# MAIN_SEC_MMR0_CFG0 register map
Vendor: Texas Instruments
Peripheral module from a debugger description file (folder J722S).
Registers are 32-bit, read-write, reset 0x0 unless marked. A register's access mark holds for its fields unless they carry their own. Offsets are as the file gives them; lines under a group give offsets from that group; [hi:lo] are bit positions; {n}, {i} and the like mark numbered series; 'fields as' and 'values as' point back to an identical list; <NAME> marks a mode.

## MAIN_SEC_MMR0_CFG0
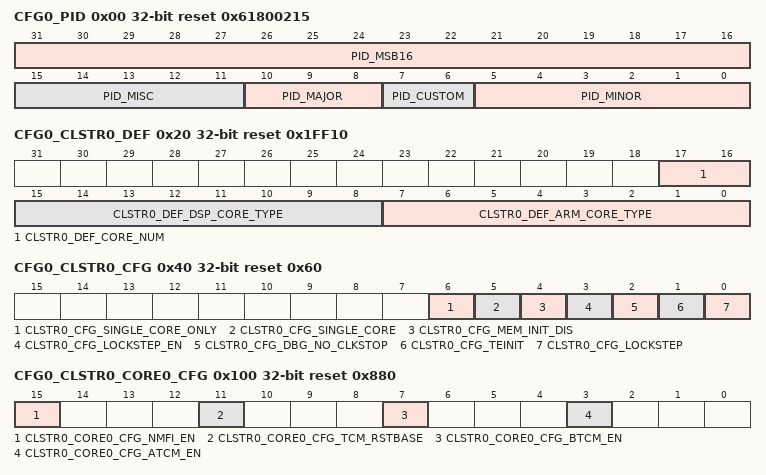
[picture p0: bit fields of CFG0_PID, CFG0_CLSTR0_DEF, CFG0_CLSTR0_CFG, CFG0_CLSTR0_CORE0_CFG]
0x00 CFG0_PID ro reset 0x61800215
  [31:16] PID_MSB16, [15:11] PID_MISC, [10:8] PID_MAJOR, [7:6] PID_CUSTOM, [5:0] PID_MINOR
0x20 CFG0_CLSTR0_DEF ro reset 0x1FF10
  [17:16] CLSTR0_DEF_CORE_NUM — Number of cores in cluster 001 - Single Core 010 - Dual Core
  [15:8] CLSTR0_DEF_DSP_CORE_TYPE — DSP core type configuration Field values (others are reserved): 8'h00 - C7x 8'h01 - C6x 8'h10 - AC7x 8'hFF - Not DSP
  [7:0] CLSTR0_DEF_ARM_CORE_TYPE — ARM core type configuration Field values (others are reserved): 8'h01 - A57 8'h10 - R5 8'h11 - M4F 8'hFF - Not ARM 8'h00 - A53 8'h01 - A57 8'h10 - R5 8'h11 - M4F 8'hFF - Not ARM
0x40 CFG0_CLSTR0_CFG access per field reset 0x60
  [6] CLSTR0_CFG_SINGLE_CORE_ONLY ro — Single / Dual CPU Mode Supported: 0 = Both Dual and Single Core are supported 1 = Only Single Core Mode is Supported
  [5] CLSTR0_CFG_SINGLE_CORE ro — Single / Dual CPU Mode: 0 = Unsupported on this device 1 = Only CPU0 is active.
  [4] CLSTR0_CFG_MEM_INIT_DIS rw — Deactivates SRAM initialization (TCM, Cache Tags, etc) at reset Initialization must be performed for proper initial ECC initialization. The mem_init_dis value must be selected prior to R5 reset assertion. 1'b0 - Perform memory initialization 1'b1 - Deactivate memory initialization
  [3] CLSTR0_CFG_LOCKSTEP_EN ro — Lockstep Not Supported
  [2] CLSTR0_CFG_DBG_NO_CLKSTOP rw — CPU clockstop behavior 0 - CPU clocks stopped and nCLOCKSTOPPED asserted in standby mode 1 - CPU clocks not stopped in standby mode
  [1] CLSTR0_CFG_TEINIT rw — Exception handling state at reset: 0 - ARM mode 1 - Thumb mode CAUTION: This bit must not be modified while R5F CPU is released from reset.
  [0] CLSTR0_CFG_LOCKSTEP ro — Lockstep Not Supported
0x80 CFG0_CLSTR0_PMCTRL access not given reset not defined
0x90 CFG0_CLSTR0_PMSTAT access not given reset not defined
0x100 CFG0_CLSTR0_CORE0_CFG reset 0x880
  [15] CLSTR0_CORE0_CFG_NMFI_EN — Activate Core0 Non-Maskable Fast Interrupts CAUTION: This bit must not be modified while R5F CPU is released from reset.
  [11] CLSTR0_CORE0_CFG_TCM_RSTBASE — Core0 A/BTCM Reset Base Address Indicator 0 - BTCM located at address 0x0 1 - ATCM located at address 0x0 CAUTION: This bit must not be modified while R5F CPU is released from reset.
  [7] CLSTR0_CORE0_CFG_BTCM_EN — Activate Core0 BTCM RAM at reset CAUTION: This bit must not be modified while R5F CPU is released from reset.
  [3] CLSTR0_CORE0_CFG_ATCM_EN — Activate Core0 ATCM RAM at reset CAUTION: This bit must not be modified while R5F CPU is released from reset.
0x110 CFG0_CLSTR0_CORE0_BOOTVECT_LO reset 0x200
  [31:7] CLSTR0_CORE0_BOOTVECT_LO_VECT_ADDR — Specifies the lower 25 bits of the 41-bit vector address corresponding to Vector Table address bits[31:7]. Note bits 6:0 of the Vector Table address are always 0.
0x114 CFG0_CLSTR0_CORE0_BOOTVECT_HI
  [15:0] CLSTR0_CORE0_BOOTVECT_HI_VECT_ADDR — Specifies the upper 16 bits of the 41-bit vector address corresponding to Vector Table address bits[47:32].
0x120 CFG0_CLSTR0_CORE0_PMCTRL
  [0] CLSTR0_CORE0_PMCTRL_CORE_HALT — Halt Core0 Field values (others are reserved): 1'b0 - CPU is held waiting to begin execution after reset is released 1'b1 - CPU is released to execute
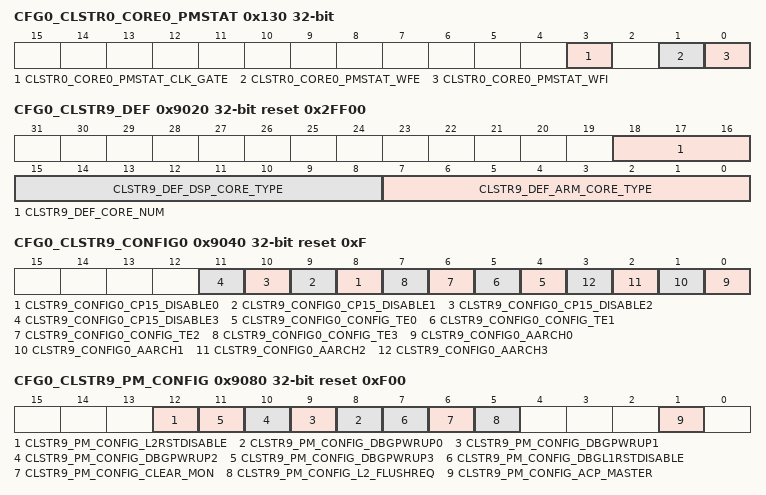
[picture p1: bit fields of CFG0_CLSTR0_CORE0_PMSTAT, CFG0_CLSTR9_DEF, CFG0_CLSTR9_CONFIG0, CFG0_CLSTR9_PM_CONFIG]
0x130 CFG0_CLSTR0_CORE0_PMSTAT ro
  [3] CLSTR0_CORE0_PMSTAT_CLK_GATE — Core0 Clocked stopped due to WFI or WFE state Note: Informaton is only valid when core is out of reset.
  [1] CLSTR0_CORE0_PMSTAT_WFE — Core0 WFE When 0, indicates that Core0 is in the WFE state Note: Informaton is only valid when core is out of reset.
  [0] CLSTR0_CORE0_PMSTAT_WFI — Core0 WFI When 0, indicates that Core0 is in the WFI state Note: Informaton is only valid when core is out of reset.
0x9020 CFG0_CLSTR9_DEF ro reset 0x2FF00
  [18:16] CLSTR9_DEF_CORE_NUM — Number of cores in cluster 000 - Single Core 001 - Dual Core 010 - Quad Core
  [15:8] CLSTR9_DEF_DSP_CORE_TYPE — DSP core type configuration Field values (others are reserved): 8'h00 - C7x 8'h01 - C6x 8'h10 - AC7x 8'hFF - Not DSP
  [7:0] CLSTR9_DEF_ARM_CORE_TYPE — ARM core type configuration Field values (others are reserved): 8'h00 - A53 8'h01 - A57 8'h10 - R5 8'h11 - M4F 8'hFF - Not ARM
0x9040 CFG0_CLSTR9_CONFIG0 reset 0xF
  [n+8] CLSTR9_CONFIG0_CP15_DISABLE{n} (n=0..3) — Deactivate write access to secure CP15 registers for Core{n} 0 - Access activated 1 - Access deactivated CAUTION: This bit must not be modified while A53 CPU is released from reset.
  [n+4] CLSTR9_CONFIG0_CONFIG_TE{n} (n=0..3) — Activate T32 exceptions for Core{n} Sets the initial value of the TE bit in the CP15 SCTLR register. This bitfield is sampled only during reset of the processor. 0 - TE bit is LOW 1 - TE bit is HIGH CAUTION: This bit must not be modified while A53 CPU is released from reset.
  [n] CLSTR9_CONFIG0_AARCH{n} (n=0..3) — Core{n} ARM Architecture configuration 0 - AArch32 1 - AArch64 CAUTION: This bit must not be modified while A53 CPU is released from reset.
0x9080 CFG0_CLSTR9_PM_CONFIG reset 0xF00
  [12] CLSTR9_PM_CONFIG_L2RSTDISABLE — Deactivate L2 cache automatic invalidate on reset functionality. This pin is sampled only during reset of the processor. 0 - Activate automatic invalidation of L2 cache on reset. 1 - Deactivate automatic invalidation of L2 cache on reset.
  [n+8] CLSTR9_PM_CONFIG_DBGPWRUP{n} (n=0..3) — Core{n} powered up 0 - Core is powered down 1 - Core is powered up
  [7] CLSTR9_PM_CONFIG_DBGL1RSTDISABLE — Deactivate L1 data cache automatic invalidate on reset functionality. This pin is sampled only during reset of the processor. 0 - Activate automatic invalidation of L1 data cache on reset. 1 - Deactivate automatic invalidation of L1 data cache on reset.
  [6] CLSTR9_PM_CONFIG_CLEAR_MON — Request to clear the external global exclusive monitor. This sends a WFE wake-up event to all cores in the cluster. When set HIGH the global exclusive monitor in the system is requesting the processor EVENT registers to be set HIGH.
  [5] CLSTR9_PM_CONFIG_L2_FLUSHREQ — ARM L2 hardware flush request
  [1] CLSTR9_PM_CONFIG_ACP_MASTER — ACP controller is inactive and is not participating in coherency. There must be no outstanding transactions when the controller asserts this signal, and while it is asserted the controller must not send any new transactions: 0 - ACP controller is active 1 - ACP controller is inactive
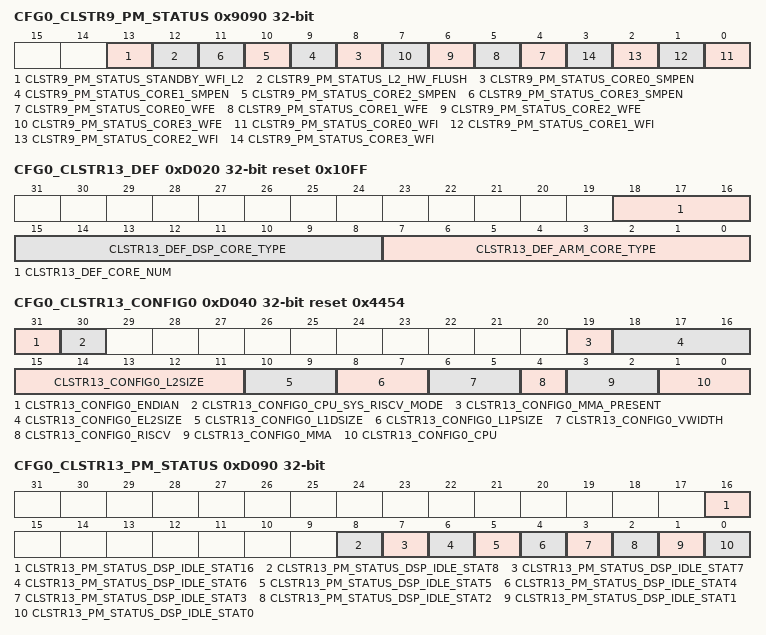
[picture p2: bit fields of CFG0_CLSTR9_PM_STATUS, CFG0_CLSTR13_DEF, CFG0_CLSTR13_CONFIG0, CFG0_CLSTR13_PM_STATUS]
0x9090 CFG0_CLSTR9_PM_STATUS ro
  [13] CLSTR9_PM_STATUS_STANDBY_WFI_L2 — Indicates L2 low power state 0 - L2 not in low power state 1 - L2 is in WFI low power state
  [12] CLSTR9_PM_STATUS_L2_HW_FLUSH — L2 hardware flush complete
  [n+8] CLSTR9_PM_STATUS_CORE{n}_SMPEN (n=0..3) — Core{n} coherency indicator 0 - Core is taking part in coherency 1 - Core is not taking part in coherency
  [n+4] CLSTR9_PM_STATUS_CORE{n}_WFE (n=0..3) — Indicates Core{n} in WFE state Note: Informaton is only valid when core is out of reset.
  [n] CLSTR9_PM_STATUS_CORE{n}_WFI (n=0..3) — Indicates Core{n} in WFI state Note: Informaton is only valid when core is out of reset.
{0x9110+0x80*i} CFG0_CLSTR9_RST_VEC_LO_CORE{i} (i=0..3)
  [31:0] CLSTR9_RST_VEC_LO_CORE{i}_RESET_BASE_VECTOR_LO — Core{i} - Reset base vector (v8 Mode) Address[33:2] CAUTION: This bit must not be modified while A53 CPU is released from reset.
{0x9114+0x80*i} CFG0_CLSTR9_RST_VEC_HI_CORE{i} (i=0..3)
  [1:0] CLSTR9_RST_VEC_HI_CORE{i}_RESET_BASE_VECTOR_HI — Core{i} - Reset base vector (v8 Mode) Address[35:34] CAUTION: This bit must not be modified while A53 CPU is released from reset.
0xD020 CFG0_CLSTR13_DEF ro reset 0x10FF
  [18:16] CLSTR13_DEF_CORE_NUM — Number of cores in cluster 000 - Single Core 001 - Dual Core 010 - Quad Core
  [15:8] CLSTR13_DEF_DSP_CORE_TYPE — DSP core type configuration Field values (others are reserved): 8'h00 - C7x 8'h01 - C6x 8'h10 - AC7x 8'hFF - Not DSP
  [7:0] CLSTR13_DEF_ARM_CORE_TYPE — ARM core type configuration Field values (others are reserved): 8'h00 - A53 8'h01 - A57 8'h10 - R5 8'h11 - M4F 8'hFF - Not ARM
0xD040 CFG0_CLSTR13_CONFIG0 access per field reset 0x4454
  [31] CLSTR13_CONFIG0_ENDIAN rw — Reset value of Endian control. Valid for DSP only. 0 - Little Endian 1 - Big Endian
  [30] CLSTR13_CONFIG0_CPU_SYS_RISCV_MODE rw — Activates CPU Booting in RiscV Mode 0 - Boot in C7x ISA Mode 1 - Boot in RiscV ISA Mode
  [19] CLSTR13_CONFIG0_MMA_PRESENT rw — MMA Present Based on EFUSE. This bit is intended to be read not modified and writes to this bit will not have any impact on the C7xv256 mma present which is directly controlled by efuse.
  [18:16] CLSTR13_CONFIG0_EL2SIZE ro — EL2 Size Field values (others are reserved): 3'b111 - 4MB 3'b110 - 3.5MB 3'b101 - 3MB 3'b100 - 2.5MB 3'b011 - 2MB 3'b010 - 1.5MB 3'b001 - 1MB 3'b000 - None
  [15:11] CLSTR13_CONFIG0_L2SIZE ro — L2 Size Field values (others are reserved): 5'b10111 - 8MB 5'b10110 - 7.5MB 5'b10101 - 7MB 5'b10100 - 6.5MB 5'b10011 - 6MB 5'b10010 - 5.5MB 5'b10001 - 5MB 5'b10000 - 4.5MB 5'b01111 - 4MB 5'b01110 - 3.75MB 5'b01101 - 3.5MB 5'b01100 - 3.25MB 5'b01011 - 3MB 5'b01010 - 2.75MB 5'b01001 - 2.5MB 5'b01000 - 2.25MB 5'b00111 - 2MB 5'b00110 - 1.75MB 5'b00101 - 1.5MB 5'b00100 - 1.25MB 5'b00011 - 1.0MB 5'b00010 - 768KB 5'b00001 - 512KB 5'b00000 - None
  [10:9] CLSTR13_CONFIG0_L1DSIZE ro — L1D Size Field values (others are reserved): 2'b11 - 128KB 2'b10 - 64KB 2'b01 - 48KB 2'b00 - 32KB
  [8:7] CLSTR13_CONFIG0_L1PSIZE ro — L1P Size Field values (others are reserved): 2'b11 - 128KB 2'b10 - 64KB 2'b01 - 48KB 2'b00 - 32KB
  [6:5] CLSTR13_CONFIG0_VWIDTH ro — Vector Width Field values (others are reserved): 2'b11 - 512b 2'b10 - 256b 2'b01 - 128b 2'b00 - 64b
  [4] CLSTR13_CONFIG0_RISCV ro — RISCV ISA SUPPORT Field values (others are reserved): 1'b1 - Supported 1'b0 - Not Supported
  [3:2] CLSTR13_CONFIG0_MMA ro — MMA Type Field values (others are reserved): 2'b11 - MMA2 2'b10 - MMA2P1 2'b01 - Reserved 2'b00 - Reserved
  [1:0] CLSTR13_CONFIG0_CPU ro — CPU Type Field values (others are reserved): 2'b11 - Reserved 2'b10 - Reserved 2'b01 - Reserved 2'b00 - AC72 R10
0xD080 CFG0_CLSTR13_PM_CONFIG access not given reset not defined
0xD090 CFG0_CLSTR13_PM_STATUS ro
  [16] CLSTR13_PM_STATUS_DSP_IDLE_STAT16 — C7x PBIST Idle Status Field values (others are reserved): 1'b1 - Idle 1'b0 - Not Idle
  [8] CLSTR13_PM_STATUS_DSP_IDLE_STAT8 — C7x DRU Idle Status Field values (others are reserved): 1'b1 - Idle 1'b0 - Not Idle
  [7] CLSTR13_PM_STATUS_DSP_IDLE_STAT7 — C7x L2 Idle Status Field values (others are reserved): 1'b1 - Idle 1'b0 - Not Idle
  [6] CLSTR13_PM_STATUS_DSP_IDLE_STAT6 — C7x Debug Idle Status Field values (others are reserved): 1'b1 - Idle 1'b0 - Not Idle
  [5] CLSTR13_PM_STATUS_DSP_IDLE_STAT5 — C7x SE Idle Status Field values (others are reserved): 1'b1 - Idle 1'b0 - Not Idle
  [4] CLSTR13_PM_STATUS_DSP_IDLE_STAT4 — C7x DMC Idle Status Field values (others are reserved): 1'b1 - Idle 1'b0 - Not Idle
  [3] CLSTR13_PM_STATUS_DSP_IDLE_STAT3 — C7x PMC Idle Status Field values (others are reserved): 1'b1 - Idle 1'b0 - Not Idle
  [2] CLSTR13_PM_STATUS_DSP_IDLE_STAT2 — C7x CPU Idle Status Field values (others are reserved): 1'b1 - Idle 1'b0 - Not Idle
  [1] CLSTR13_PM_STATUS_DSP_IDLE_STAT1 — C7x Core LPSC Idle Status Field values (others are reserved): 1'b1 - Idle 1'b0 - Not Idle
  [0] CLSTR13_PM_STATUS_DSP_IDLE_STAT0 — Composite Idle Status Field values (others are reserved): 1'b1 - Idle 1'b0 - Not Idle
0xD100 CFG0_CLSTR13_CORE0_CFG access not given reset not defined
0xD110 CFG0_CLSTR13_RST_VEC_LO_CORE0
  [31:0] CLSTR13_RST_VEC_LO_CORE0_RESET_BASE_VECTOR_LO — Reset Vector Base Address 33:2 for C7x DSP
0xD114 CFG0_CLSTR13_RST_VEC_HI_CORE0
  [1:0] CLSTR13_RST_VEC_HI_CORE0_RESET_BASE_VECTOR_HI — Reset Vector Base Address 35:34 for C7x DSP
0xD120 CFG0_CLSTR13_CORE0_PMCTRL access not given reset not defined
0xD130 CFG0_CLSTR13_CORE0_PMSTAT access not given reset not defined
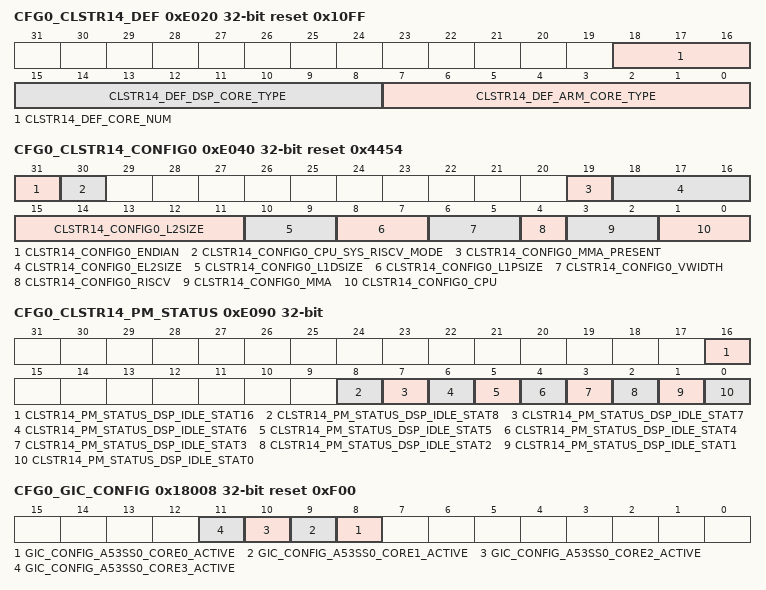
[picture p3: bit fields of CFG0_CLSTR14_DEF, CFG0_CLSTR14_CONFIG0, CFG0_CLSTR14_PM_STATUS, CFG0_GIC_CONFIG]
0xE020 CFG0_CLSTR14_DEF ro reset 0x10FF
  [18:16] CLSTR14_DEF_CORE_NUM — Number of cores in cluster 000 - Single Core 001 - Dual Core 010 - Quad Core
  [15:8] CLSTR14_DEF_DSP_CORE_TYPE — DSP core type configuration Field values (others are reserved): 8'h00 - C7x 8'h01 - C6x 8'h10 - AC7x 8'hFF - Not DSP
  [7:0] CLSTR14_DEF_ARM_CORE_TYPE — ARM core type configuration Field values (others are reserved): 8'h00 - A53 8'h01 - A57 8'h10 - R5 8'h11 - M4F 8'hFF - Not ARM
0xE040 CFG0_CLSTR14_CONFIG0 access per field reset 0x4454
  [31] CLSTR14_CONFIG0_ENDIAN rw — Reset value of Endian control. Valid for DSP only. 0 - Little Endian 1 - Big Endian
  [30] CLSTR14_CONFIG0_CPU_SYS_RISCV_MODE rw — Activates CPU Booting in RiscV Mode 0 - Boot in C7x ISA Mode 1 - Boot in RiscV ISA Mode
  [19] CLSTR14_CONFIG0_MMA_PRESENT rw — MMA Present Based on EFUSE. This bit is intended to be read not modified and writes to this bit will not have any impact on the C7xv256 mma present which is directly controlled by efuse.
  [18:16] CLSTR14_CONFIG0_EL2SIZE ro — EL2 Size Field values (others are reserved): 3'b111 - 4MB 3'b110 - 3.5MB 3'b101 - 3MB 3'b100 - 2.5MB 3'b011 - 2MB 3'b010 - 1.5MB 3'b001 - 1MB 3'b000 - None
  [15:11] CLSTR14_CONFIG0_L2SIZE ro — L2 Size Field values (others are reserved): 5'b10111 - 8MB 5'b10110 - 7.5MB 5'b10101 - 7MB 5'b10100 - 6.5MB 5'b10011 - 6MB 5'b10010 - 5.5MB 5'b10001 - 5MB 5'b10000 - 4.5MB 5'b01111 - 4MB 5'b01110 - 3.75MB 5'b01101 - 3.5MB 5'b01100 - 3.25MB 5'b01011 - 3MB 5'b01010 - 2.75MB 5'b01001 - 2.5MB 5'b01000 - 2.25MB 5'b00111 - 2MB 5'b00110 - 1.75MB 5'b00101 - 1.5MB 5'b00100 - 1.25MB 5'b00011 - 1.0MB 5'b00010 - 768KB 5'b00001 - 512KB 5'b00000 - None
  [10:9] CLSTR14_CONFIG0_L1DSIZE ro — L1D Size Field values (others are reserved): 2'b11 - 128KB 2'b10 - 64KB 2'b01 - 48KB 2'b00 - 32KB
  [8:7] CLSTR14_CONFIG0_L1PSIZE ro — L1P Size Field values (others are reserved): 2'b11 - 128KB 2'b10 - 64KB 2'b01 - 48KB 2'b00 - 32KB
  [6:5] CLSTR14_CONFIG0_VWIDTH ro — Vector Width Field values (others are reserved): 2'b11 - 512b 2'b10 - 256b 2'b01 - 128b 2'b00 - 64b
  [4] CLSTR14_CONFIG0_RISCV ro — RISCV ISA SUPPORT Field values (others are reserved): 1'b1 - Supported 1'b0 - Not Supported
  [3:2] CLSTR14_CONFIG0_MMA ro — MMA Type Field values (others are reserved): 2'b11 - MMA2 2'b10 - MMA2P1 2'b01 - Reserved 2'b00 - Reserved
  [1:0] CLSTR14_CONFIG0_CPU ro — CPU Type Field values (others are reserved): 2'b11 - Reserved 2'b10 - Reserved 2'b01 - Reserved 2'b00 - AC72 R10
0xE080 CFG0_CLSTR14_PM_CONFIG access not given reset not defined
0xE090 CFG0_CLSTR14_PM_STATUS ro
  [16] CLSTR14_PM_STATUS_DSP_IDLE_STAT16 — C7x PBIST Idle Status Field values (others are reserved): 1'b1 - Idle 1'b0 - Not Idle
  [8] CLSTR14_PM_STATUS_DSP_IDLE_STAT8 — C7x DRU Idle Status Field values (others are reserved): 1'b1 - Idle 1'b0 - Not Idle
  [7] CLSTR14_PM_STATUS_DSP_IDLE_STAT7 — C7x L2 Idle Status Field values (others are reserved): 1'b1 - Idle 1'b0 - Not Idle
  [6] CLSTR14_PM_STATUS_DSP_IDLE_STAT6 — C7x Debug Idle Status Field values (others are reserved): 1'b1 - Idle 1'b0 - Not Idle
  [5] CLSTR14_PM_STATUS_DSP_IDLE_STAT5 — C7x SE Idle Status Field values (others are reserved): 1'b1 - Idle 1'b0 - Not Idle
  [4] CLSTR14_PM_STATUS_DSP_IDLE_STAT4 — C7x DMC Idle Status Field values (others are reserved): 1'b1 - Idle 1'b0 - Not Idle
  [3] CLSTR14_PM_STATUS_DSP_IDLE_STAT3 — C7x PMC Idle Status Field values (others are reserved): 1'b1 - Idle 1'b0 - Not Idle
  [2] CLSTR14_PM_STATUS_DSP_IDLE_STAT2 — C7x CPU Idle Status Field values (others are reserved): 1'b1 - Idle 1'b0 - Not Idle
  [1] CLSTR14_PM_STATUS_DSP_IDLE_STAT1 — C7x Core LPSC Idle Status Field values (others are reserved): 1'b1 - Idle 1'b0 - Not Idle
  [0] CLSTR14_PM_STATUS_DSP_IDLE_STAT0 — Composite Idle Status Field values (others are reserved): 1'b1 - Idle 1'b0 - Not Idle
0xE100 CFG0_CLSTR14_CORE0_CFG access not given reset not defined
0xE110 CFG0_CLSTR14_RST_VEC_LO_CORE0
  [31:0] CLSTR14_RST_VEC_LO_CORE0_RESET_BASE_VECTOR_LO — Reset Vector Base Address 33:2 for C7x DSP
0xE114 CFG0_CLSTR14_RST_VEC_HI_CORE0
  [1:0] CLSTR14_RST_VEC_HI_CORE0_RESET_BASE_VECTOR_HI — Reset Vector Base Address 35:34 for C7x DSP
0xE120 CFG0_CLSTR14_CORE0_PMCTRL access not given reset not defined
0xE130 CFG0_CLSTR14_CORE0_PMSTAT access not given reset not defined
0x18008 CFG0_GIC_CONFIG reset 0xF00
  [n+8] GIC_CONFIG_A53SS0_CORE{n}_ACTIVE (n=0..3) — Drives GIC cpu_active input for A53SS0 Core{n}. When a core is in a low-power mode (cpu_active=0), the GIC will not route shared-SPI events to the core which would wake up the core resulting in increased power consumption. 0 - Core is in a software-transparent low power mode 1 - Core is active and available for shared SPIs
